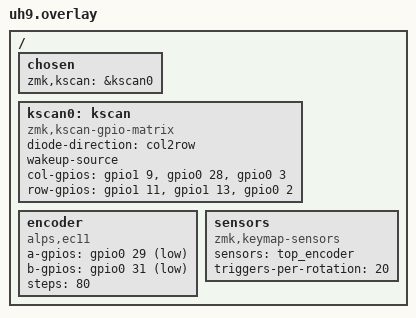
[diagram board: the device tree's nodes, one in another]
#include <dt-bindings/zmk/matrix_transform.h>

/ {
    chosen {
\        zmk,kscan = &kscan0;
    };

    kscan0: kscan {
        compatible = "zmk,kscan-gpio-matrix";
        diode-direction = "col2row";
        wakeup-source;

        col-gpios
            = <&gpio1  9 GPIO_ACTIVE_HIGH>
            , <&gpio0 28 GPIO_ACTIVE_HIGH>
            , <&gpio0  3 GPIO_ACTIVE_HIGH>
            ;

        row-gpios
           = <&gpio1 11 (GPIO_ACTIVE_HIGH | GPIO_PULL_DOWN)>
           , <&gpio1 13 (GPIO_ACTIVE_HIGH | GPIO_PULL_DOWN)>
           , <&gpio0  2 (GPIO_ACTIVE_HIGH | GPIO_PULL_DOWN)>
           ;

    };

    encoder: encoder {
        compatible = "alps,ec11";
        a-gpios = <&gpio0 29 (GPIO_ACTIVE_LOW | GPIO_PULL_UP)>;
        b-gpios = <&gpio0 31 (GPIO_ACTIVE_LOW | GPIO_PULL_UP)>;
        steps = <80>;
        status = "okay";
    };

    sensors: sensors {
        compatible = "zmk,keymap-sensors";
        sensors = <&top_encoder>;
        triggers-per-rotation = <20>;
    };

};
